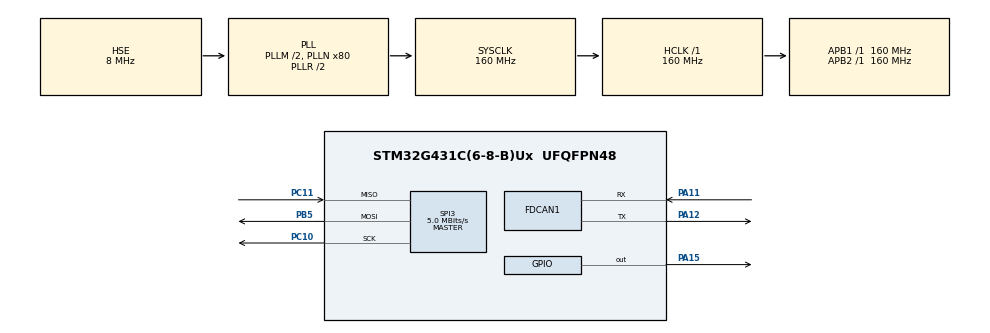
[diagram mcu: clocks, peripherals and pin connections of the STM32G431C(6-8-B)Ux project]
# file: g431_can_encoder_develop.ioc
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FDCAN1.AutoRetransmission=ENABLE
FDCAN1.CalculateBaudRateNominal=1000000
FDCAN1.CalculateTimeBitNominal=1000
FDCAN1.CalculateTimeQuantumNominal=6.25
FDCAN1.DataSyncJumpWidth=16
FDCAN1.DataTimeSeg1=20
FDCAN1.DataTimeSeg2=11
FDCAN1.ExtFiltersNbr=1
FDCAN1.FrameFormat=FDCAN_FRAME_FD_BRS
FDCAN1.NominalPrescaler=1
FDCAN1.NominalSyncJumpWidth=16
FDCAN1.NominalTimeSeg1=110
FDCAN1.NominalTimeSeg2=49
FDCAN1.ProtocolException=ENABLE
FDCAN1.StdFiltersNbr=1
FDCAN1.TransmitPause=ENABLE
Mcu.Family=STM32G4
Mcu.Name=STM32G431C(6-8-B)Ux
Mcu.Package=UFQFPN48
NVIC.FDCAN1_IT0_IRQn=true\:0\:0\:false\:false\:true\:true\:true\:true
NVIC.PriorityGroup=NVIC_PRIORITYGROUP_4
NVIC.TIM1_BRK_TIM15_IRQn=true\:0\:0\:false\:false\:true\:true\:true\:true
NVIC.TIM1_UP_TIM16_IRQn=true\:0\:0\:false\:false\:true\:true\:true\:true
PA11.Mode=FDCAN_Activate
PA11.Signal=FDCAN1_RX
PA12.Mode=FDCAN_Activate
PA12.Signal=FDCAN1_TX
PA13.Mode=Serial_Wire
PA13.Signal=SYS_JTMS-SWDIO
PA14.Mode=Serial_Wire
PA14.Signal=SYS_JTCK-SWCLK
PA15.Signal=GPIO_Output
PB5.Mode=Full_Duplex_Master
PB5.Signal=SPI3_MOSI
PC10.Mode=Full_Duplex_Master
PC10.Signal=SPI3_SCK
PC11.Mode=Full_Duplex_Master
PC11.Signal=SPI3_MISO
PF0-OSC_IN.Mode=HSE-External-Oscillator
PF0-OSC_IN.Signal=RCC_OSC_IN
PF1-OSC_OUT.Mode=HSE-External-Oscillator
PF1-OSC_OUT.Signal=RCC_OSC_OUT
ProjectManager.HeapSize=0x200
ProjectManager.StackSize=0x400
ProjectManager.TargetToolchain=MDK-ARM V5.32
RCC.ADC12Freq_Value=160000000
RCC.AHBFreq_Value=160000000
RCC.APB1Freq_Value=160000000
RCC.APB1TimFreq_Value=160000000
RCC.APB2Freq_Value=160000000
RCC.APB2TimFreq_Value=160000000
RCC.CortexFreq_Value=160000000
RCC.EXTERNAL_CLOCK_VALUE=12288000
RCC.HCLKFreq_Value=160000000
RCC.HSE_VALUE=8000000
RCC.HSI48_VALUE=48000000
RCC.HSI_VALUE=16000000
RCC.LSE_VALUE=32768
RCC.PLLM=RCC_PLLM_DIV2
RCC.PLLN=80
RCC.PLLSourceVirtual=RCC_PLLSOURCE_HSE
RCC.SYSCLKFreq_VALUE=160000000
RCC.SYSCLKSource=RCC_SYSCLKSOURCE_PLLCLK
RCC.USBFreq_Value=160000000
RCC.VCOOutputFreq_Value=320000000
SPI3.BaudRatePrescaler=SPI_BAUDRATEPRESCALER_32
SPI3.CLKPhase=SPI_PHASE_2EDGE
SPI3.CalculateBaudRate=5.0 MBits/s
SPI3.DataSize=SPI_DATASIZE_16BIT
SPI3.Direction=SPI_DIRECTION_2LINES
SPI3.Mode=SPI_MODE_MASTER
SPI3.VirtualType=VM_MASTER
TIM15.AutoReloadPreload=TIM_AUTORELOAD_PRELOAD_ENABLE
TIM15.PeriodNoDither=1000-1
TIM15.Prescaler=160-1
TIM16.PeriodNoDither=1000 - 1
TIM16.Prescaler=40 - 1
VP_SYS_VS_DBSignals.Mode=DisableDeadBatterySignals
VP_TIM15_VS_ClockSourceINT.Mode=Internal
VP_TIM16_VS_ClockSourceINT.Mode=Enable_Timer
board=custom

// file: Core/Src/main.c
/* USER CODE BEGIN Header */
/**
  ******************************************************************************
  * @file           : main.c
  * @brief          : Main program body
  ******************************************************************************
  * @attention
  *
  * Copyright (c) 2024 STMicroelectronics.
  * All rights reserved.
  *
  * This software is licensed under terms that can be found in the LICENSE file
  * in the root directory of this software component.
  * If no LICENSE file comes with this software, it is provided AS-IS.
  *
  ******************************************************************************
  */
/* USER CODE END Header */
#include "main.h"
#include "fdcan.h"
#include "spi.h"
#include "tim.h"
#include "gpio.h"

/* USER CODE BEGIN Includes */
#include "fdcan_bsp.h"
#include "AS5047.h"
#include "can_encoder.h"
/* USER CODE END Includes */

void SystemClock_Config(void);

int main(void)
{

  /* MCU Configuration--------------------------------------------------------*/

  /* Reset of all peripherals, Initializes the Flash interface and the Systick. */
  HAL_Init();

  /* Configure the system clock */
  SystemClock_Config();

  /* Initialize all configured peripherals */
  MX_GPIO_Init();
  MX_FDCAN1_Init();
  MX_SPI3_Init();
  MX_TIM15_Init();
  MX_TIM16_Init();
  /* USER CODE BEGIN 2 */
  usDelayOptimize();
  /* USER CODE END 2 */

  /* Infinite loop */
  while (1)
  {

  }
}

void SystemClock_Config(void)
{
  RCC_OscInitTypeDef RCC_OscInitStruct = {0};
  RCC_ClkInitTypeDef RCC_ClkInitStruct = {0};

  /** Configure the main internal regulator output voltage
  */
  HAL_PWREx_ControlVoltageScaling(PWR_REGULATOR_VOLTAGE_SCALE1_BOOST);

  /** Initializes the RCC Oscillators according to the specified parameters
  * in the RCC_OscInitTypeDef structure.
  */
  RCC_OscInitStruct.OscillatorType = RCC_OSCILLATORTYPE_HSE;
  RCC_OscInitStruct.HSEState = RCC_HSE_ON;
  RCC_OscInitStruct.PLL.PLLState = RCC_PLL_ON;
  RCC_OscInitStruct.PLL.PLLSource = RCC_PLLSOURCE_HSE;
  RCC_OscInitStruct.PLL.PLLM = RCC_PLLM_DIV2;
  RCC_OscInitStruct.PLL.PLLN = 80;
  RCC_OscInitStruct.PLL.PLLP = RCC_PLLP_DIV2;
  RCC_OscInitStruct.PLL.PLLQ = RCC_PLLQ_DIV2;
  RCC_OscInitStruct.PLL.PLLR = RCC_PLLR_DIV2;
  if (HAL_RCC_OscConfig(&RCC_OscInitStruct) != HAL_OK)
  {
    Error_Handler();
  }

  /** Initializes the CPU, AHB and APB buses clocks
  */
  RCC_ClkInitStruct.ClockType = RCC_CLOCKTYPE_HCLK|RCC_CLOCKTYPE_SYSCLK
                              |RCC_CLOCKTYPE_PCLK1|RCC_CLOCKTYPE_PCLK2;
  RCC_ClkInitStruct.SYSCLKSource = RCC_SYSCLKSOURCE_PLLCLK;
  RCC_ClkInitStruct.AHBCLKDivider = RCC_SYSCLK_DIV1;
  RCC_ClkInitStruct.APB1CLKDivider = RCC_HCLK_DIV1;
  RCC_ClkInitStruct.APB2CLKDivider = RCC_HCLK_DIV1;

  if (HAL_RCC_ClockConfig(&RCC_ClkInitStruct, FLASH_LATENCY_4) != HAL_OK)
  {
    Error_Handler();
  }
}

/* USER CODE BEGIN 4 */
void HAL_TIM_PeriodElapsedCallback(TIM_HandleTypeDef *htim) {
  if (htim->Instance == TIM15) {
    send_angle();
  }
  if (htim->Instance == TIM16) {
    as5047_read_angle_routine(&as5047[0]);
  }
}

/* USER CODE END 4 */

void Error_Handler(void)
{
  __disable_irq();
  while (1)
  {
  }
}
